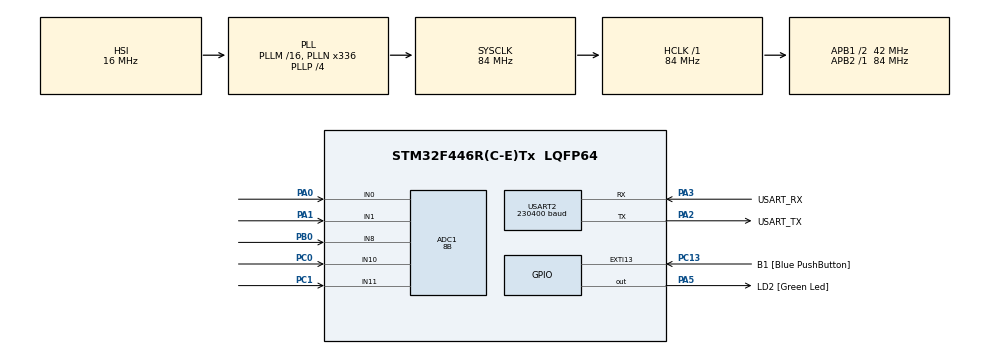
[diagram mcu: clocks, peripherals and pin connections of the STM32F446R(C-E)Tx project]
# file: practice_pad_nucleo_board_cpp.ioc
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ADC1.Channel-0\#ChannelRegularConversion=ADC_CHANNEL_0
ADC1.Channel-1\#ChannelRegularConversion=ADC_CHANNEL_1
ADC1.Channel-2\#ChannelRegularConversion=ADC_CHANNEL_8
ADC1.Channel-3\#ChannelRegularConversion=ADC_CHANNEL_10
ADC1.Channel-4\#ChannelRegularConversion=ADC_CHANNEL_11
ADC1.ContinuousConvMode=ENABLE
ADC1.DMAContinuousRequests=DISABLE
ADC1.DataAlign=ADC_DATAALIGN_RIGHT
ADC1.EOCSelection=ADC_EOC_SEQ_CONV
ADC1.NbrOfConversion=5
ADC1.NbrOfConversionFlag=1
ADC1.Rank-0\#ChannelRegularConversion=1
ADC1.Rank-1\#ChannelRegularConversion=2
ADC1.Rank-2\#ChannelRegularConversion=3
ADC1.Rank-3\#ChannelRegularConversion=4
ADC1.Rank-4\#ChannelRegularConversion=5
ADC1.Resolution=ADC_RESOLUTION_8B
ADC1.SamplingTime-0\#ChannelRegularConversion=ADC_SAMPLETIME_3CYCLES
ADC1.SamplingTime-1\#ChannelRegularConversion=ADC_SAMPLETIME_3CYCLES
ADC1.SamplingTime-2\#ChannelRegularConversion=ADC_SAMPLETIME_3CYCLES
ADC1.SamplingTime-3\#ChannelRegularConversion=ADC_SAMPLETIME_3CYCLES
ADC1.SamplingTime-4\#ChannelRegularConversion=ADC_SAMPLETIME_3CYCLES
ADC1.master=1
Dma.ADC1.0.Direction=DMA_PERIPH_TO_MEMORY
Dma.ADC1.0.FIFOMode=DMA_FIFOMODE_DISABLE
Dma.ADC1.0.Instance=DMA2_Stream0
Dma.ADC1.0.MemDataAlignment=DMA_MDATAALIGN_WORD
Dma.ADC1.0.MemInc=DMA_MINC_ENABLE
Dma.ADC1.0.Mode=DMA_NORMAL
Dma.ADC1.0.PeriphDataAlignment=DMA_PDATAALIGN_WORD
Dma.ADC1.0.PeriphInc=DMA_PINC_DISABLE
Dma.ADC1.0.Priority=DMA_PRIORITY_HIGH
Dma.Request0=ADC1
Dma.Request1=USART2_TX
Dma.Request2=USART2_RX
Dma.USART2_RX.2.Direction=DMA_PERIPH_TO_MEMORY
Dma.USART2_RX.2.FIFOMode=DMA_FIFOMODE_DISABLE
Dma.USART2_RX.2.Instance=DMA1_Stream5
Dma.USART2_RX.2.MemDataAlignment=DMA_MDATAALIGN_BYTE
Dma.USART2_RX.2.MemInc=DMA_MINC_ENABLE
Dma.USART2_RX.2.Mode=DMA_CIRCULAR
Dma.USART2_RX.2.PeriphDataAlignment=DMA_PDATAALIGN_BYTE
Dma.USART2_RX.2.PeriphInc=DMA_PINC_DISABLE
Dma.USART2_RX.2.Priority=DMA_PRIORITY_LOW
Dma.USART2_TX.1.Direction=DMA_MEMORY_TO_PERIPH
Dma.USART2_TX.1.FIFOMode=DMA_FIFOMODE_DISABLE
Dma.USART2_TX.1.Instance=DMA1_Stream6
Dma.USART2_TX.1.MemDataAlignment=DMA_MDATAALIGN_BYTE
Dma.USART2_TX.1.MemInc=DMA_MINC_ENABLE
Dma.USART2_TX.1.Mode=DMA_NORMAL
Dma.USART2_TX.1.PeriphDataAlignment=DMA_PDATAALIGN_BYTE
Dma.USART2_TX.1.PeriphInc=DMA_PINC_DISABLE
Dma.USART2_TX.1.Priority=DMA_PRIORITY_LOW
FREERTOS.Tasks01=defaultTask,24,128,StartDefaultTask,Default,NULL,Dynamic,NULL,NULL
Mcu.Family=STM32F4
Mcu.Name=STM32F446R(C-E)Tx
Mcu.Package=LQFP64
NVIC.DMA1_Stream5_IRQn=true\:5\:0\:false\:false\:true\:true\:false\:true\:true
NVIC.DMA1_Stream6_IRQn=true\:5\:0\:false\:false\:true\:true\:false\:true\:true
NVIC.DMA2_Stream0_IRQn=true\:5\:0\:false\:false\:true\:true\:false\:true\:true
NVIC.PriorityGroup=NVIC_PRIORITYGROUP_4
NVIC.TIM3_IRQn=true\:5\:0\:false\:false\:true\:true\:true\:true\:true
NVIC.TIM7_IRQn=true\:15\:0\:false\:false\:true\:false\:false\:true\:true
NVIC.TimeBase=TIM7_IRQn
NVIC.TimeBaseIP=TIM7
NVIC.USART2_IRQn=true\:5\:0\:false\:false\:true\:true\:true\:true\:true
PA0-WKUP.Signal=ADCx_IN0
PA1.Signal=ADCx_IN1
PA13.GPIO_Label=TMS
PA13.Mode=Trace_Asynchronous_SW
PA13.Signal=SYS_JTMS-SWDIO
PA14.GPIO_Label=TCK
PA14.Mode=Trace_Asynchronous_SW
PA14.Signal=SYS_JTCK-SWCLK
PA2.GPIO_Label=USART_TX
PA2.Mode=Asynchronous
PA2.Signal=USART2_TX
PA3.GPIO_Label=USART_RX
PA3.Mode=Asynchronous
PA3.Signal=USART2_RX
PA5.GPIO_Label=LD2 [Green Led]
PA5.Signal=GPIO_Output
PB0.Signal=ADCx_IN8
PB3.GPIO_Label=SWO
PB3.Mode=Trace_Asynchronous_SW
PB3.Signal=SYS_JTDO-SWO
PC0.Signal=ADCx_IN10
PC1.Signal=ADCx_IN11
PC13.GPIO_Label=B1 [Blue PushButton]
PC13.GPIO_ModeDefaultEXTI=GPIO_MODE_IT_FALLING
PC13.Signal=GPXTI13
PC14-OSC32_IN.Mode=LSE-External-Oscillator
PC14-OSC32_IN.Signal=RCC_OSC32_IN
PC15-OSC32_OUT.Mode=LSE-External-Oscillator
PC15-OSC32_OUT.Signal=RCC_OSC32_OUT
PH0-OSC_IN.Mode=HSE-External-Oscillator
PH0-OSC_IN.Signal=RCC_OSC_IN
PH1-OSC_OUT.Mode=HSE-External-Oscillator
PH1-OSC_OUT.Signal=RCC_OSC_OUT
ProjectManager.HeapSize=0x200
ProjectManager.StackSize=0x400
ProjectManager.TargetToolchain=CMake
RCC.48MHZClocksFreq_Value=84000000
RCC.AHBFreq_Value=84000000
RCC.APB1CLKDivider=RCC_HCLK_DIV2
RCC.APB1Freq_Value=42000000
RCC.APB1TimFreq_Value=84000000
RCC.APB2Freq_Value=84000000
RCC.APB2TimFreq_Value=84000000
RCC.CortexFreq_Value=84000000
RCC.FLatency-AdvancedSettings=FLASH_LATENCY_2
RCC.HCLKFreq_Value=84000000
RCC.HSE_VALUE=8000000
RCC.HSI_VALUE=16000000
RCC.PLLN=336
RCC.PLLP=RCC_PLLP_DIV4
RCC.SYSCLKFreq_VALUE=84000000
RCC.SYSCLKSource=RCC_SYSCLKSOURCE_PLLCLK
RCC.USBFreq_Value=168000000
RCC.VCOOutputFreq_Value=336000000
SH.ADCx_IN0.0=ADC1_IN0,IN0
SH.ADCx_IN1.0=ADC1_IN1,IN1
SH.ADCx_IN10.0=ADC1_IN10,IN10
SH.ADCx_IN11.0=ADC1_IN11,IN11
SH.ADCx_IN8.0=ADC1_IN8,IN8
TIM3.Period=10000 - 1
TIM3.Prescaler=8400 - 1
USART2.BaudRate=230400
USART2.VirtualMode=VM_ASYNC
VP_FREERTOS_VS_CMSIS_V2.Mode=CMSIS_V2
VP_SYS_VS_tim7.Mode=TIM7
VP_TIM3_VS_ClockSourceINT.Mode=Internal
board=NUCLEO-F446RE

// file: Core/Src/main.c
/* USER CODE BEGIN Header */
/**
  ******************************************************************************
  * @file           : main.c
  * @brief          : Main program body
  ******************************************************************************
  * @attention
  *
  * Copyright (c) 2025 STMicroelectronics.
  * All rights reserved.
  *
  * This software is licensed under terms that can be found in the LICENSE file
  * in the root directory of this software component.
  * If no LICENSE file comes with this software, it is provided AS-IS.
  *
  ******************************************************************************
  */
/* USER CODE END Header */
#include "main.h"
#include "cmsis_os.h"
#include "adc.h"
#include "dma.h"
#include "tim.h"
#include "usart.h"
#include "gpio.h"

/* USER CODE BEGIN Includes */
#include "semphr.h"
#include "cpp_main.h"
/* USER CODE END Includes */

void SystemClock_Config(void);
void MX_FREERTOS_Init(void);

/* USER CODE BEGIN 0 */
extern SemaphoreHandle_t xmetronome_timer_period_elapsed;
/* USER CODE END 0 */

int main(void)
{

  /* MCU Configuration--------------------------------------------------------*/

  /* Reset of all peripherals, Initializes the Flash interface and the Systick. */
  HAL_Init();

  /* Configure the system clock */
  SystemClock_Config();

  /* Initialize all configured peripherals */
  MX_GPIO_Init();
  MX_DMA_Init();
  MX_ADC1_Init();
  MX_USART2_UART_Init();
  MX_TIM3_Init();
  /* USER CODE BEGIN 2 */
  /* Init scheduler */
  osKernelInitialize();

  /* Call init function for freertos objects (in cmsis_os2.c) */
  MX_FREERTOS_Init();
  cpp_main();
  /* USER CODE END 2 */

  /* Init scheduler */
  osKernelInitialize();

  /* Call init function for freertos objects (in cmsis_os2.c) */
  MX_FREERTOS_Init();

  /* Start scheduler */
  osKernelStart();

  /* We should never get here as control is now taken by the scheduler */

  /* Infinite loop */
  while (1)
  {

  }
}

void SystemClock_Config(void)
{
  RCC_OscInitTypeDef RCC_OscInitStruct = {0};
  RCC_ClkInitTypeDef RCC_ClkInitStruct = {0};

  /** Configure the main internal regulator output voltage
  */
  __HAL_RCC_PWR_CLK_ENABLE();
  __HAL_PWR_VOLTAGESCALING_CONFIG(PWR_REGULATOR_VOLTAGE_SCALE3);

  /** Initializes the RCC Oscillators according to the specified parameters
  * in the RCC_OscInitTypeDef structure.
  */
  RCC_OscInitStruct.OscillatorType = RCC_OSCILLATORTYPE_HSI;
  RCC_OscInitStruct.HSIState = RCC_HSI_ON;
  RCC_OscInitStruct.HSICalibrationValue = RCC_HSICALIBRATION_DEFAULT;
  RCC_OscInitStruct.PLL.PLLState = RCC_PLL_ON;
  RCC_OscInitStruct.PLL.PLLSource = RCC_PLLSOURCE_HSI;
  RCC_OscInitStruct.PLL.PLLM = 16;
  RCC_OscInitStruct.PLL.PLLN = 336;
  RCC_OscInitStruct.PLL.PLLP = RCC_PLLP_DIV4;
  RCC_OscInitStruct.PLL.PLLQ = 2;
  RCC_OscInitStruct.PLL.PLLR = 2;
  if (HAL_RCC_OscConfig(&RCC_OscInitStruct) != HAL_OK)
  {
    Error_Handler();
  }

  /** Initializes the CPU, AHB and APB buses clocks
  */
  RCC_ClkInitStruct.ClockType = RCC_CLOCKTYPE_HCLK|RCC_CLOCKTYPE_SYSCLK
                              |RCC_CLOCKTYPE_PCLK1|RCC_CLOCKTYPE_PCLK2;
  RCC_ClkInitStruct.SYSCLKSource = RCC_SYSCLKSOURCE_PLLCLK;
  RCC_ClkInitStruct.AHBCLKDivider = RCC_SYSCLK_DIV1;
  RCC_ClkInitStruct.APB1CLKDivider = RCC_HCLK_DIV2;
  RCC_ClkInitStruct.APB2CLKDivider = RCC_HCLK_DIV1;

  if (HAL_RCC_ClockConfig(&RCC_ClkInitStruct, FLASH_LATENCY_2) != HAL_OK)
  {
    Error_Handler();
  }
}

void HAL_TIM_PeriodElapsedCallback(TIM_HandleTypeDef *htim)
{
  /* USER CODE BEGIN Callback 0 */
  if (htim->Instance == TIM3) {
    // metronome tick
    static portBASE_TYPE xHigherPriorityTaskWoken = pdFALSE;
    xSemaphoreGiveFromISR(xmetronome_timer_period_elapsed, &xHigherPriorityTaskWoken);
    /* If giving a semaphore caused a task to unblock, and the unblocked task
    has a priority equal to or higher than the currently running task (the task
    this ISR interrupted), then higher_priority_task_woken will have
    automatically been set to pdTRUE within the semaphore function.
    portEND_SWITCHING_ISR() will then ensure that this ISR returns directly to
    the higher priority unblocked task. */
    portEND_SWITCHING_ISR(xHigherPriorityTaskWoken);
  }
  /* USER CODE END Callback 0 */
  if (htim->Instance == TIM7) {
    HAL_IncTick();
  }
  /* USER CODE BEGIN Callback 1 */
  //if (htim->Instance == TIM1) {
    //printf("tim\n");
  //}
  /* USER CODE END Callback 1 */
}

void Error_Handler(void)
{
  __disable_irq();
  while (1)
  {
  }
}
